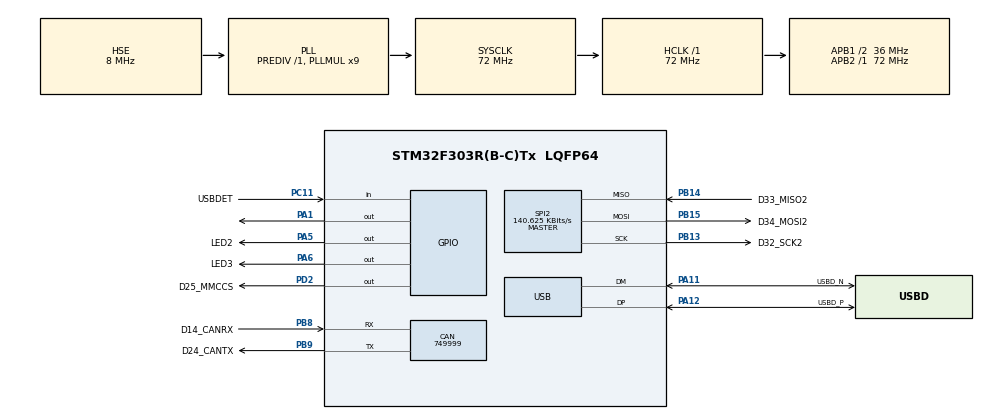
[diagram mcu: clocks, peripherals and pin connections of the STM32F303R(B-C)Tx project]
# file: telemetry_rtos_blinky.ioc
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CAN.CalculateBaudRate=749999
CAN.CalculateTimeBit=1333
CAN.CalculateTimeQuantum=444.44444444444446
Mcu.Family=STM32F3
Mcu.Name=STM32F303R(B-C)Tx
Mcu.Package=LQFP64
NVIC.PriorityGroup=NVIC_PRIORITYGROUP_4
NVIC.TIM1_UP_TIM16_IRQn=true\:15\:0\:false\:false\:true\:false\:true\:true
NVIC.TimeBase=TIM1_UP_TIM16_IRQn
NVIC.TimeBaseIP=TIM1
PA1.Signal=GPIO_Output
PA11.GPIO_Label=USBD_N
PA11.Mode=Device
PA11.Signal=USB_DM
PA12.GPIO_Label=USBD_P
PA12.Mode=Device
PA12.Signal=USB_DP
PA13.GPIO_Label=TMS_SWDIO
PA13.Mode=Serial_Wire
PA13.Signal=SYS_JTMS-SWDIO
PA14.GPIO_Label=TCK_SWCLK
PA14.Mode=Serial_Wire
PA14.Signal=SYS_JTCK-SWCLK
PA5.GPIO_Label=LED2
PA5.Signal=GPIO_Output
PA6.GPIO_Label=LED3
PA6.Signal=GPIO_Output
PB10.GPIO_Label=D29_USART3TX
PB10.Signal=USART3_TX
PB11.GPIO_Label=D30_USART3RX
PB11.Signal=USART3_RX
PB13.GPIO_Label=D32_SCK2
PB13.Mode=Full_Duplex_Master
PB13.Signal=SPI2_SCK
PB14.GPIO_Label=D33_MISO2
PB14.Mode=Full_Duplex_Master
PB14.Signal=SPI2_MISO
PB15.GPIO_Label=D34_MOSI2
PB15.Mode=Full_Duplex_Master
PB15.Signal=SPI2_MOSI
PB3.GPIO_Label=TDO_SWO
PB3.Signal=SYS_JTDO-TRACESWO
PB8.GPIO_Label=D14_CANRX
PB8.Mode=CAN_Activate
PB8.Signal=CAN_RX
PB8.Stacked=true
PB9.GPIO_Label=D24_CANTX
PB9.Mode=CAN_Activate
PB9.Signal=CAN_TX
PC11.GPIO_Label=USBDET
PC11.Signal=GPIO_Input
PC14-OSC32_IN.Mode=LSE-External-Oscillator
PC14-OSC32_IN.Signal=RCC_OSC32_IN
PC15-OSC32_OUT.Mode=LSE-External-Oscillator
PC15-OSC32_OUT.Signal=RCC_OSC32_OUT
PD2.GPIO_Label=D25_MMCCS 
PD2.Signal=GPIO_Output
PF0-OSC_IN.Mode=HSE-External-Oscillator
PF0-OSC_IN.Signal=RCC_OSC_IN
PF1-OSC_OUT.Mode=HSE-External-Oscillator
PF1-OSC_OUT.Signal=RCC_OSC_OUT
ProjectManager.HeapSize=0x200
ProjectManager.StackSize=0x400
ProjectManager.TargetToolchain=CMake
RCC.AHBFreq_Value=72000000
RCC.APB1CLKDivider=RCC_HCLK_DIV2
RCC.APB1Freq_Value=36000000
RCC.APB1TimFreq_Value=72000000
RCC.APB2Freq_Value=72000000
RCC.APB2TimFreq_Value=72000000
RCC.CortexFreq_Value=72000000
RCC.EnbaleCSS=true
RCC.HCLKFreq_Value=72000000
RCC.HSE_VALUE=8000000
RCC.HSI_VALUE=8000000
RCC.PLLMUL=RCC_PLL_MUL9
RCC.PRESCALERUSB=RCC_USBCLKSOURCE_PLL_DIV1_5
RCC.RTCClockSelection=RCC_RTCCLKSOURCE_LSE
RCC.SYSCLKFreq_VALUE=72000000
RCC.SYSCLKSourceVirtual=RCC_SYSCLKSOURCE_PLLCLK
RCC.USBFreq_Value=48000000
SPI2.BaudRatePrescaler=SPI_BAUDRATEPRESCALER_256
SPI2.CalculateBaudRate=140.625 KBits/s
SPI2.DataSize=SPI_DATASIZE_8BIT
SPI2.Direction=SPI_DIRECTION_2LINES
SPI2.Mode=SPI_MODE_MASTER
SPI2.VirtualType=VM_MASTER
VP_FATFS_VS_Generic.Mode=User_defined
VP_RTC_VS_RTC_Activate.Mode=RTC_Enabled
VP_SYS_VS_tim1.Mode=TIM1
board=custom

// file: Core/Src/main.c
/* USER CODE BEGIN Header */
/**
  ******************************************************************************
  * @file           : main.c
  * @brief          : Main program body
  ******************************************************************************
  * @attention
  *
  * Copyright (c) 2026 STMicroelectronics.
  * All rights reserved.
  *
  * This software is licensed under terms that can be found in the LICENSE file
  * in the root directory of this software component.
  * If no LICENSE file comes with this software, it is provided AS-IS.
  *
  ******************************************************************************
  */
/* USER CODE END Header */
#include "main.h"
#include "fatfs.h"

/* USER CODE BEGIN Includes */
#include "blink_tasks.h"
/* USER CODE END Includes */

CAN_HandleTypeDef hcan;

RTC_HandleTypeDef hrtc;

SPI_HandleTypeDef hspi2;

PCD_HandleTypeDef hpcd_USB_FS;

void SystemClock_Config(void);
static void MX_GPIO_Init(void);
static void MX_CAN_Init(void);
static void MX_RTC_Init(void);
static void MX_USB_PCD_Init(void);
static void MX_SPI2_Init(void);

int main(void)
{

  /* MCU Configuration--------------------------------------------------------*/

  /* Reset of all peripherals, Initializes the Flash interface and the Systick. */
  HAL_Init();

  /* Configure the system clock */
  SystemClock_Config();

  /* Initialize all configured peripherals */
  MX_GPIO_Init();
  MX_CAN_Init();
  MX_RTC_Init();
  MX_USB_PCD_Init();
  MX_SPI2_Init();
  MX_FATFS_Init();

  /* Infinite loop */
  while (1)
  {

  }
}

void SystemClock_Config(void)
{
  RCC_OscInitTypeDef RCC_OscInitStruct = {0};
  RCC_ClkInitTypeDef RCC_ClkInitStruct = {0};
  RCC_PeriphCLKInitTypeDef PeriphClkInit = {0};

  /** Configure LSE Drive Capability
  */
  HAL_PWR_EnableBkUpAccess();
  __HAL_RCC_LSEDRIVE_CONFIG(RCC_LSEDRIVE_LOW);

  /** Initializes the RCC Oscillators according to the specified parameters
  * in the RCC_OscInitTypeDef structure.
  */
  RCC_OscInitStruct.OscillatorType = RCC_OSCILLATORTYPE_HSE|RCC_OSCILLATORTYPE_LSE;
  RCC_OscInitStruct.HSEState = RCC_HSE_ON;
  RCC_OscInitStruct.HSEPredivValue = RCC_HSE_PREDIV_DIV1;
  RCC_OscInitStruct.LSEState = RCC_LSE_ON;
  RCC_OscInitStruct.HSIState = RCC_HSI_ON;
  RCC_OscInitStruct.PLL.PLLState = RCC_PLL_ON;
  RCC_OscInitStruct.PLL.PLLSource = RCC_PLLSOURCE_HSE;
  RCC_OscInitStruct.PLL.PLLMUL = RCC_PLL_MUL9;
  if (HAL_RCC_OscConfig(&RCC_OscInitStruct) != HAL_OK)
  {
    Error_Handler();
  }

  /** Initializes the CPU, AHB and APB buses clocks
  */
  RCC_ClkInitStruct.ClockType = RCC_CLOCKTYPE_HCLK|RCC_CLOCKTYPE_SYSCLK
                              |RCC_CLOCKTYPE_PCLK1|RCC_CLOCKTYPE_PCLK2;
  RCC_ClkInitStruct.SYSCLKSource = RCC_SYSCLKSOURCE_PLLCLK;
  RCC_ClkInitStruct.AHBCLKDivider = RCC_SYSCLK_DIV1;
  RCC_ClkInitStruct.APB1CLKDivider = RCC_HCLK_DIV2;
  RCC_ClkInitStruct.APB2CLKDivider = RCC_HCLK_DIV1;

  if (HAL_RCC_ClockConfig(&RCC_ClkInitStruct, FLASH_LATENCY_2) != HAL_OK)
  {
    Error_Handler();
  }
  PeriphClkInit.PeriphClockSelection = RCC_PERIPHCLK_USB|RCC_PERIPHCLK_RTC;
  PeriphClkInit.RTCClockSelection = RCC_RTCCLKSOURCE_LSE;
  PeriphClkInit.USBClockSelection = RCC_USBCLKSOURCE_PLL_DIV1_5;
  if (HAL_RCCEx_PeriphCLKConfig(&PeriphClkInit) != HAL_OK)
  {
    Error_Handler();
  }

  /** Enables the Clock Security System
  */
  HAL_RCC_EnableCSS();
}

static void MX_CAN_Init(void)
{

  hcan.Instance = CAN;
  hcan.Init.Prescaler = 16;
  hcan.Init.Mode = CAN_MODE_NORMAL;
  hcan.Init.SyncJumpWidth = CAN_SJW_1TQ;
  hcan.Init.TimeSeg1 = CAN_BS1_1TQ;
  hcan.Init.TimeSeg2 = CAN_BS2_1TQ;
  hcan.Init.TimeTriggeredMode = DISABLE;
  hcan.Init.AutoBusOff = DISABLE;
  hcan.Init.AutoWakeUp = DISABLE;
  hcan.Init.AutoRetransmission = DISABLE;
  hcan.Init.ReceiveFifoLocked = DISABLE;
  hcan.Init.TransmitFifoPriority = DISABLE;
  if (HAL_CAN_Init(&hcan) != HAL_OK)
  {
    Error_Handler();
  }

}

static void MX_RTC_Init(void)
{

  /** Initialize RTC Only
  */
  hrtc.Instance = RTC;
  hrtc.Init.HourFormat = RTC_HOURFORMAT_24;
  hrtc.Init.AsynchPrediv = 127;
  hrtc.Init.SynchPrediv = 255;
  hrtc.Init.OutPut = RTC_OUTPUT_DISABLE;
  hrtc.Init.OutPutPolarity = RTC_OUTPUT_POLARITY_HIGH;
  hrtc.Init.OutPutType = RTC_OUTPUT_TYPE_OPENDRAIN;
  if (HAL_RTC_Init(&hrtc) != HAL_OK)
  {
    Error_Handler();
  }

}

static void MX_SPI2_Init(void)
{

  /* SPI2 parameter configuration*/
  hspi2.Instance = SPI2;
  hspi2.Init.Mode = SPI_MODE_MASTER;
  hspi2.Init.Direction = SPI_DIRECTION_2LINES;
  hspi2.Init.DataSize = SPI_DATASIZE_8BIT;
  hspi2.Init.CLKPolarity = SPI_POLARITY_LOW;
  hspi2.Init.CLKPhase = SPI_PHASE_1EDGE;
  hspi2.Init.NSS = SPI_NSS_SOFT;
  hspi2.Init.BaudRatePrescaler = SPI_BAUDRATEPRESCALER_256;
  hspi2.Init.FirstBit = SPI_FIRSTBIT_MSB;
  hspi2.Init.TIMode = SPI_TIMODE_DISABLE;
  hspi2.Init.CRCCalculation = SPI_CRCCALCULATION_DISABLE;
  hspi2.Init.CRCPolynomial = 7;
  hspi2.Init.CRCLength = SPI_CRC_LENGTH_DATASIZE;
  hspi2.Init.NSSPMode = SPI_NSS_PULSE_ENABLE;
  if (HAL_SPI_Init(&hspi2) != HAL_OK)
  {
    Error_Handler();
  }

}

static void MX_USB_PCD_Init(void)
{

  hpcd_USB_FS.Instance = USB;
  hpcd_USB_FS.Init.dev_endpoints = 8;
  hpcd_USB_FS.Init.speed = PCD_SPEED_FULL;
  hpcd_USB_FS.Init.phy_itface = PCD_PHY_EMBEDDED;
  hpcd_USB_FS.Init.low_power_enable = DISABLE;
  hpcd_USB_FS.Init.battery_charging_enable = DISABLE;
  if (HAL_PCD_Init(&hpcd_USB_FS) != HAL_OK)
  {
    Error_Handler();
  }

}

static void MX_GPIO_Init(void)
{
  GPIO_InitTypeDef GPIO_InitStruct = {0};

  /* GPIO Ports Clock Enable */
  __HAL_RCC_GPIOC_CLK_ENABLE();
  __HAL_RCC_GPIOF_CLK_ENABLE();
  __HAL_RCC_GPIOA_CLK_ENABLE();
  __HAL_RCC_GPIOB_CLK_ENABLE();
  __HAL_RCC_GPIOD_CLK_ENABLE();

  /*Configure GPIO pin Output Level */
  HAL_GPIO_WritePin(GPIOA, GPIO_PIN_1|LED2_Pin|LED3_Pin, GPIO_PIN_RESET);

  /*Configure GPIO pin Output Level */
  HAL_GPIO_WritePin(D25_MMCCS_GPIO_Port, D25_MMCCS_Pin, GPIO_PIN_RESET);

  /*Configure GPIO pins : PA1 LED2_Pin LED3_Pin */
  GPIO_InitStruct.Pin = GPIO_PIN_1|LED2_Pin|LED3_Pin;
  GPIO_InitStruct.Mode = GPIO_MODE_OUTPUT_PP;
  GPIO_InitStruct.Pull = GPIO_NOPULL;
  GPIO_InitStruct.Speed = GPIO_SPEED_FREQ_LOW;
  HAL_GPIO_Init(GPIOA, &GPIO_InitStruct);

  /*Configure GPIO pins : D29_USART3TX_Pin D30_USART3RX_Pin */
  GPIO_InitStruct.Pin = D29_USART3TX_Pin|D30_USART3RX_Pin;
  GPIO_InitStruct.Mode = GPIO_MODE_AF_PP;
  GPIO_InitStruct.Pull = GPIO_NOPULL;
  GPIO_InitStruct.Speed = GPIO_SPEED_FREQ_HIGH;
  GPIO_InitStruct.Alternate = GPIO_AF7_USART3;
  HAL_GPIO_Init(GPIOB, &GPIO_InitStruct);

  /*Configure GPIO pin : USBDET_Pin */
  GPIO_InitStruct.Pin = USBDET_Pin;
  GPIO_InitStruct.Mode = GPIO_MODE_INPUT;
  GPIO_InitStruct.Pull = GPIO_NOPULL;
  HAL_GPIO_Init(USBDET_GPIO_Port, &GPIO_InitStruct);

  /*Configure GPIO pin : D25_MMCCS_Pin */
  GPIO_InitStruct.Pin = D25_MMCCS_Pin;
  GPIO_InitStruct.Mode = GPIO_MODE_OUTPUT_PP;
  GPIO_InitStruct.Pull = GPIO_NOPULL;
  GPIO_InitStruct.Speed = GPIO_SPEED_FREQ_LOW;
  HAL_GPIO_Init(D25_MMCCS_GPIO_Port, &GPIO_InitStruct);

}

void HAL_TIM_PeriodElapsedCallback(TIM_HandleTypeDef *htim)
{
  if (htim->Instance == TIM1)
  {
    HAL_IncTick();
  }
}

void Error_Handler(void)
{
  __disable_irq();
  while (1)
  {
  }
}
